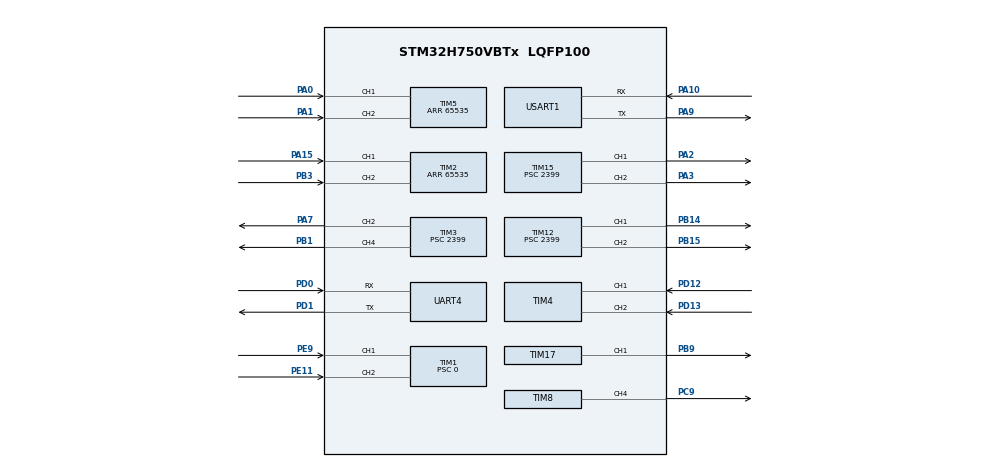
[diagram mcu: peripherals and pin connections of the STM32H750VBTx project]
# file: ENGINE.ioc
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FREERTOS.INCLUDE_vTaskDelayUntil=1
FREERTOS.Tasks01=defaultTask,-2,64,StartDefaultTask,Default,NULL,Dynamic,NULL,NULL;CHASSIS,0,128,CHASSIS_TASK,As external,NULL,Dynamic,NULL,NULL
FREERTOS.configMINIMAL_STACK_SIZE=64
Mcu.Family=STM32H7
Mcu.Name=STM32H750VBTx
Mcu.Package=LQFP100
NVIC.PriorityGroup=NVIC_PRIORITYGROUP_4
NVIC.TIM6_DAC_IRQn=true\:15\:0\:false\:false\:true\:false\:false\:true\:true
NVIC.TimeBase=TIM6_DAC_IRQn
NVIC.TimeBaseIP=TIM6
NVIC.UART4_IRQn=true\:5\:0\:false\:false\:true\:true\:true\:true\:true
NVIC.USART1_IRQn=true\:5\:0\:false\:false\:true\:true\:true\:true\:true
PA0.Signal=S_TIM5_CH1
PA1.Signal=S_TIM5_CH2
PA10.Mode=Asynchronous
PA10.Signal=USART1_RX
PA13\ (JTMS/SWDIO).Mode=Serial_Wire
PA13\ (JTMS/SWDIO).Signal=DEBUG_JTMS-SWDIO
PA14\ (JTCK/SWCLK).Mode=Serial_Wire
PA14\ (JTCK/SWCLK).Signal=DEBUG_JTCK-SWCLK
PA15\ (JTDI).Signal=S_TIM2_CH1_ETR
PA2.GPIO_PuPd=GPIO_NOPULL
PA2.Signal=S_TIM15_CH1
PA3.GPIO_PuPd=GPIO_NOPULL
PA3.Signal=S_TIM15_CH2
PA7.GPIO_PuPd=GPIO_NOPULL
PA7.Signal=S_TIM3_CH2
PA9.Mode=Asynchronous
PA9.Signal=USART1_TX
PB1.Signal=S_TIM3_CH4
PB14.Signal=S_TIM12_CH1
PB15.Signal=S_TIM12_CH2
PB3\ (JTDO/TRACESWO).Signal=S_TIM2_CH2
PB9.Signal=S_TIM17_CH1
PC14-OSC32_IN\ (OSC32_IN).Mode=LSE-External-Oscillator
PC14-OSC32_IN\ (OSC32_IN).Signal=RCC_OSC32_IN
PC15-OSC32_OUT\ (OSC32_OUT).Mode=LSE-External-Oscillator
PC15-OSC32_OUT\ (OSC32_OUT).Signal=RCC_OSC32_OUT
PC9.Signal=S_TIM8_CH4
PD0.Mode=Asynchronous
PD0.Signal=UART4_RX
PD1.Mode=Asynchronous
PD1.Signal=UART4_TX
PD12.Signal=S_TIM4_CH1
PD13.Signal=S_TIM4_CH2
PE11.GPIO_PuPd=GPIO_PULLUP
PE11.Signal=S_TIM1_CH2
PE9.GPIO_PuPd=GPIO_PULLUP
PE9.Signal=S_TIM1_CH1
PH0-OSC_IN\ (PH0).Mode=HSE-External-Oscillator
PH0-OSC_IN\ (PH0).Signal=RCC_OSC_IN
PH1-OSC_OUT\ (PH1).Mode=HSE-External-Oscillator
PH1-OSC_OUT\ (PH1).Signal=RCC_OSC_OUT
ProjectManager.HeapSize=0x1000
ProjectManager.StackSize=0x2000
ProjectManager.TargetToolchain=MDK-ARM V5.32
RCC.ADCFreq_Value=50390625
RCC.APB1Freq_Value=120000000
RCC.APB2Freq_Value=120000000
RCC.APB3Freq_Value=120000000
RCC.APB4Freq_Value=120000000
RCC.CortexFreq_Value=480000000
RCC.D1PPRE=RCC_APB3_DIV2
RCC.D2PPRE1=RCC_APB1_DIV2
RCC.D2PPRE2=RCC_APB2_DIV2
RCC.D3PPRE=RCC_APB4_DIV2
RCC.DIVM1=5
RCC.DIVN1=192
RCC.HCLKFreq_Value=240000000
RCC.HPRE=RCC_HCLK_DIV2
RCC.HSE_VALUE=25000000
RCC.PLL2FRACN=0
RCC.PLL3FRACN=0
RCC.PLLFRACN=0
RCC.PLLSourceVirtual=RCC_PLLSOURCE_HSE
RCC.SYSCLKFreq_VALUE=480000000
RCC.SYSCLKSource=RCC_SYSCLKSOURCE_PLLCLK
RCC.USBFreq_Value=480000000
SH.S_TIM12_CH1.0=TIM12_CH1,PWM Generation1 CH1
SH.S_TIM12_CH2.0=TIM12_CH2,PWM Generation2 CH2
SH.S_TIM15_CH1.0=TIM15_CH1,PWM Generation1 CH1
SH.S_TIM15_CH2.0=TIM15_CH2,PWM Generation2 CH2
SH.S_TIM17_CH1.0=TIM17_CH1,PWM Generation1 CH1
SH.S_TIM1_CH1.0=TIM1_CH1,Encoder_Interface
SH.S_TIM1_CH2.0=TIM1_CH2,Encoder_Interface
SH.S_TIM2_CH1_ETR.0=TIM2_CH1,Encoder_Interface
SH.S_TIM2_CH2.0=TIM2_CH2,Encoder_Interface
SH.S_TIM3_CH2.0=TIM3_CH2,PWM Generation2 CH2
SH.S_TIM3_CH4.0=TIM3_CH4,PWM Generation4 CH4
SH.S_TIM4_CH1.0=TIM4_CH1,Encoder_Interface
SH.S_TIM4_CH2.0=TIM4_CH2,Encoder_Interface
SH.S_TIM5_CH1.0=TIM5_CH1,Encoder_Interface
SH.S_TIM5_CH2.0=TIM5_CH2,Encoder_Interface
SH.S_TIM8_CH4.0=TIM8_CH4,PWM Generation4 CH4
TIM1.EncoderMode=TIM_ENCODERMODE_TI12
TIM1.IC1Filter=15
TIM1.IC2Filter=15
TIM1.Prescaler=0
TIM12.AutoReloadPreload=TIM_AUTORELOAD_PRELOAD_ENABLE
TIM12.Channel-PWM\ Generation1\ CH1=TIM_CHANNEL_1
TIM12.Channel-PWM\ Generation2\ CH2=TIM_CHANNEL_2
TIM12.Period=1999
TIM12.Prescaler=2399
TIM15.AutoReloadPreload=TIM_AUTORELOAD_PRELOAD_ENABLE
TIM15.Channel-PWM\ Generation1\ CH1=TIM_CHANNEL_1
TIM15.Channel-PWM\ Generation2\ CH2=TIM_CHANNEL_2
TIM15.Period=1999
TIM15.Prescaler=2399
TIM15.Pulse-PWM\ Generation2\ CH2=999
TIM17.AutoReloadPreload=TIM_AUTORELOAD_PRELOAD_ENABLE
TIM17.Channel=TIM_CHANNEL_1
TIM17.Period=1999
TIM17.Prescaler=2399
TIM2.Period=65535
TIM3.AutoReloadPreload=TIM_AUTORELOAD_PRELOAD_ENABLE
TIM3.Channel-PWM\ Generation2\ CH2=TIM_CHANNEL_2
TIM3.Channel-PWM\ Generation4\ CH4=TIM_CHANNEL_4
TIM3.Period=1999
TIM3.Prescaler=2399
TIM5.Period=65535
TIM8.AutoReloadPreload=TIM_AUTORELOAD_PRELOAD_ENABLE
TIM8.Channel-PWM\ Generation4\ CH4=TIM_CHANNEL_4
TIM8.Period=1999
TIM8.Prescaler=2399
TIM8.Pulse-PWM\ Generation4\ CH4=999
USART1.VirtualMode-Asynchronous=VM_ASYNC
VP_FREERTOS_VS_CMSIS_V1.Mode=CMSIS_V1
VP_SYS_VS_tim6.Mode=TIM6
VP_TIM12_VS_ClockSourceINT.Mode=Internal
VP_TIM15_VS_ClockSourceINT.Mode=Internal
VP_TIM17_VS_ClockSourceINT.Mode=Enable_Timer
VP_TIM3_VS_ClockSourceINT.Mode=Internal
VP_TIM8_VS_ClockSourceINT.Mode=Internal
board=custom

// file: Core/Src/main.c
/* USER CODE BEGIN Header */
/**
  ******************************************************************************
  * @file           : main.c
  * @brief          : Main program body
  ******************************************************************************
  * @attention
  *
  * Copyright (c) 2022 STMicroelectronics.
  * All rights reserved.
  *
  * This software is licensed under terms that can be found in the LICENSE file
  * in the root directory of this software component.
  * If no LICENSE file comes with this software, it is provided AS-IS.
  *
  ******************************************************************************
  */
/* USER CODE END Header */
#include "main.h"
#include "cmsis_os.h"
#include "tim.h"
#include "usart.h"
#include "gpio.h"

void SystemClock_Config(void);
void MX_FREERTOS_Init(void);

int main(void)
{

  /* MCU Configuration--------------------------------------------------------*/

  /* Reset of all peripherals, Initializes the Flash interface and the Systick. */
  HAL_Init();

  /* Configure the system clock */
  SystemClock_Config();

  /* Initialize all configured peripherals */
  MX_GPIO_Init();
  MX_TIM8_Init();
  MX_TIM15_Init();
  MX_TIM3_Init();
  MX_TIM12_Init();
  MX_TIM17_Init();
  MX_TIM1_Init();
  MX_UART4_Init();
  MX_TIM2_Init();
  MX_TIM4_Init();
  MX_TIM5_Init();
  MX_USART1_UART_Init();
  /* USER CODE BEGIN 2 */
	/*ENGINE ENABLE
		int32_t pwm;
		int32_t a = 0;
		HAL_TIM_PWM_Start (&htim15, TIM_CHANNEL_2);
		HAL_TIM_PWM_Start (&htim8, TIM_CHANNEL_4);
		HAL_TIM_PWM_Start (&htim3, TIM_CHANNEL_4);
		HAL_TIM_PWM_Start (&htim3, TIM_CHANNEL_2);
		HAL_TIM_PWM_Start (&htim12, TIM_CHANNEL_2);
		HAL_TIM_PWM_Start (&htim12, TIM_CHANNEL_1);
		HAL_TIM_PWM_Start (&htim15, TIM_CHANNEL_1);
		HAL_TIM_PWM_Start (&htim17, TIM_CHANNEL_1);
		HAL_TIM_Encoder_Start(&htim1, TIM_CHANNEL_ALL);*/

  /* USER CODE END 2 */

  /* Call init function for freertos objects (in freertos.c) */
  MX_FREERTOS_Init();

  /* Start scheduler */
  osKernelStart();

  /* We should never get here as control is now taken by the scheduler */
  /* Infinite loop */
  /* USER CODE BEGIN WHILE */
  while (1)
  {
		/*round*/
		/*if (a == 0)
		{
			__HAL_TIM_SetCompare (&htim15, TIM_CHANNEL_2, pwm); //m2+
			__HAL_TIM_SetCompare (&htim8, TIM_CHANNEL_4, 0);  //m2-
			__HAL_TIM_SetCompare (&htim3, TIM_CHANNEL_2, 0);  //m1-
			__HAL_TIM_SetCompare (&htim3, TIM_CHANNEL_4, pwm);	//m1+
			__HAL_TIM_SetCompare (&htim12, TIM_CHANNEL_2, 0);  //m3-
			__HAL_TIM_SetCompare (&htim12, TIM_CHANNEL_1, pwm);  //m3+
			__HAL_TIM_SetCompare (&htim15, TIM_CHANNEL_1, pwm);  //m4+
			__HAL_TIM_SetCompare (&htim17, TIM_CHANNEL_1, 0);   //m4-
		  HAL_Delay (5000);
			a = 1;
		}*/
		/*move*/
		/*if (a == 1)
		{
			__HAL_TIM_SetCompare (&htim15, TIM_CHANNEL_2, pwm); //m2+
			__HAL_TIM_SetCompare (&htim8, TIM_CHANNEL_4, 0);  //m2-
			__HAL_TIM_SetCompare (&htim3, TIM_CHANNEL_2, 0);  //m1-
			__HAL_TIM_SetCompare (&htim3, TIM_CHANNEL_4, pwm);	//m1+
			__HAL_TIM_SetCompare (&htim12, TIM_CHANNEL_2, pwm);  //m3-
			__HAL_TIM_SetCompare (&htim12, TIM_CHANNEL_1, 0);  //m3+
			__HAL_TIM_SetCompare (&htim15, TIM_CHANNEL_1, 0);  //m4+
			__HAL_TIM_SetCompare (&htim17, TIM_CHANNEL_1, pwm);  //m4-
			HAL_Delay (5000);
			a = 0;
		}*/

    /* USER CODE END WHILE */

  }
}

void SystemClock_Config(void)
{
  RCC_OscInitTypeDef RCC_OscInitStruct = {0};
  RCC_ClkInitTypeDef RCC_ClkInitStruct = {0};

  /** Supply configuration update enable
  */
  HAL_PWREx_ConfigSupply(PWR_LDO_SUPPLY);

  /** Configure the main internal regulator output voltage
  */
  __HAL_PWR_VOLTAGESCALING_CONFIG(PWR_REGULATOR_VOLTAGE_SCALE1);

  while(!__HAL_PWR_GET_FLAG(PWR_FLAG_VOSRDY)) {}

  __HAL_RCC_SYSCFG_CLK_ENABLE();
  __HAL_PWR_VOLTAGESCALING_CONFIG(PWR_REGULATOR_VOLTAGE_SCALE0);

  while(!__HAL_PWR_GET_FLAG(PWR_FLAG_VOSRDY)) {}

  /** Initializes the RCC Oscillators according to the specified parameters
  * in the RCC_OscInitTypeDef structure.
  */
  RCC_OscInitStruct.OscillatorType = RCC_OSCILLATORTYPE_HSE;
  RCC_OscInitStruct.HSEState = RCC_HSE_ON;
  RCC_OscInitStruct.PLL.PLLState = RCC_PLL_ON;
  RCC_OscInitStruct.PLL.PLLSource = RCC_PLLSOURCE_HSE;
  RCC_OscInitStruct.PLL.PLLM = 5;
  RCC_OscInitStruct.PLL.PLLN = 192;
  RCC_OscInitStruct.PLL.PLLP = 2;
  RCC_OscInitStruct.PLL.PLLQ = 2;
  RCC_OscInitStruct.PLL.PLLR = 2;
  RCC_OscInitStruct.PLL.PLLRGE = RCC_PLL1VCIRANGE_2;
  RCC_OscInitStruct.PLL.PLLVCOSEL = RCC_PLL1VCOWIDE;
  RCC_OscInitStruct.PLL.PLLFRACN = 0;
  if (HAL_RCC_OscConfig(&RCC_OscInitStruct) != HAL_OK)
  {
    Error_Handler();
  }

  /** Initializes the CPU, AHB and APB buses clocks
  */
  RCC_ClkInitStruct.ClockType = RCC_CLOCKTYPE_HCLK|RCC_CLOCKTYPE_SYSCLK
                              |RCC_CLOCKTYPE_PCLK1|RCC_CLOCKTYPE_PCLK2
                              |RCC_CLOCKTYPE_D3PCLK1|RCC_CLOCKTYPE_D1PCLK1;
  RCC_ClkInitStruct.SYSCLKSource = RCC_SYSCLKSOURCE_PLLCLK;
  RCC_ClkInitStruct.SYSCLKDivider = RCC_SYSCLK_DIV1;
  RCC_ClkInitStruct.AHBCLKDivider = RCC_HCLK_DIV2;
  RCC_ClkInitStruct.APB3CLKDivider = RCC_APB3_DIV2;
  RCC_ClkInitStruct.APB1CLKDivider = RCC_APB1_DIV2;
  RCC_ClkInitStruct.APB2CLKDivider = RCC_APB2_DIV2;
  RCC_ClkInitStruct.APB4CLKDivider = RCC_APB4_DIV2;

  if (HAL_RCC_ClockConfig(&RCC_ClkInitStruct, FLASH_LATENCY_4) != HAL_OK)
  {
    Error_Handler();
  }
}

void HAL_TIM_PeriodElapsedCallback(TIM_HandleTypeDef *htim)
{
  if (htim->Instance == TIM6) {
    HAL_IncTick();
  }
}

void Error_Handler(void)
{
  __disable_irq();
  while (1)
  {
  }
}

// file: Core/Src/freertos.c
/* USER CODE BEGIN Header */
/**
  ******************************************************************************
  * File Name          : freertos.c
  * Description        : Code for freertos applications
  ******************************************************************************
  * @attention
  *
  * Copyright (c) 2022 STMicroelectronics.
  * All rights reserved.
  *
  * This software is licensed under terms that can be found in the LICENSE file
  * in the root directory of this software component.
  * If no LICENSE file comes with this software, it is provided AS-IS.
  *
  ******************************************************************************
  */
/* USER CODE END Header */

#include "FreeRTOS.h"
#include "task.h"
#include "main.h"
#include "cmsis_os.h"

osThreadId defaultTaskHandle;
osThreadId CHASSISHandle;

void StartDefaultTask(void const * argument);
extern void CHASSIS_TASK(void const * argument);

void MX_FREERTOS_Init(void); /* (MISRA C 2004 rule 8.1) */

/* GetIdleTaskMemory prototype (linked to static allocation support) */
void vApplicationGetIdleTaskMemory( StaticTask_t **ppxIdleTaskTCBBuffer, StackType_t **ppxIdleTaskStackBuffer, uint32_t *pulIdleTaskStackSize );

/* USER CODE BEGIN GET_IDLE_TASK_MEMORY */
static StaticTask_t xIdleTaskTCBBuffer;
static StackType_t xIdleStack[configMINIMAL_STACK_SIZE];

void vApplicationGetIdleTaskMemory( StaticTask_t **ppxIdleTaskTCBBuffer, StackType_t **ppxIdleTaskStackBuffer, uint32_t *pulIdleTaskStackSize )
{
  *ppxIdleTaskTCBBuffer = &xIdleTaskTCBBuffer;
  *ppxIdleTaskStackBuffer = &xIdleStack[0];
  *pulIdleTaskStackSize = configMINIMAL_STACK_SIZE;
  /* place for user code */
}
/* USER CODE END GET_IDLE_TASK_MEMORY */

void MX_FREERTOS_Init(void) {

  /* Create the thread(s) */
  /* definition and creation of defaultTask */
  osThreadDef(defaultTask, StartDefaultTask, osPriorityLow, 0, 64);
  defaultTaskHandle = osThreadCreate(osThread(defaultTask), NULL);

  /* definition and creation of CHASSIS */
  osThreadDef(CHASSIS, CHASSIS_TASK, osPriorityNormal, 0, 128);
  CHASSISHandle = osThreadCreate(osThread(CHASSIS), NULL);

}

void StartDefaultTask(void const * argument)
{
  for(;;)
  {
    osDelay(1);
  }
}
